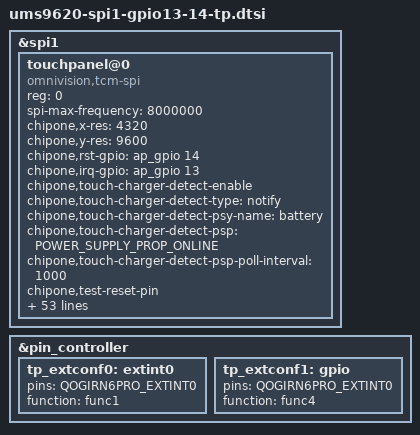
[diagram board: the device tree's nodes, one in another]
// SPDX-License-Identifier: (GPL-2.0+ OR MIT)
/*
 * Unisoc TP dts file
 *
 * Copyright (C) 2020, Unisoc Inc.
 *
 */
&spi1 {
	status = "ok";
	#address-cells = <1>;
	#size-cells = <0>;

	/* Novatek device tree node */
	touchpanel@0 {
		compatible = "omnivision,tcm-spi","tchip,ilitek","novatek,NVT-ts-spi","chipone-tddi";
		reg = <0>; //Same as CS ID
		status = "ok";
		spi-max-frequency = <8000000>;	//4800000,9600000,15000000,19200000

		/*chipone-tddi start*/
		chipone,x-res = <4320>;
		chipone,y-res = <9600>;
		chipone,rst-gpio = <&ap_gpio 14 GPIO_ACTIVE_HIGH>;
		chipone,irq-gpio = <&ap_gpio 13 GPIO_ACTIVE_HIGH>;

		/* Charger detect */
		chipone,touch-charger-detect-enable;
		chipone,touch-charger-detect-type = "notify"; /* notify, poll */
		chipone,touch-charger-detect-psy-name = "battery";
		chipone,touch-charger-detect-psp = "POWER_SUPPLY_PROP_ONLINE";
		chipone,touch-charger-detect-psp-poll-interval = <1000>;

		/* Factory test parameter */
		chipone,test-reset-pin;
		chipone,test-int-pin;
		chipone,test-rawdata;
		chipone,test-rawdata-frames      = <1>;
		chipone,rawdata-min              = <1200>;	//base2000, ±40%
		chipone,rawdata-max              = <2800>;
		chipone,test-noise;
		chipone,test-noise-frames        = <50>;
		chipone,noise-max                = <80>;
		chipone,test-open;
		chipone,open-min                 = <1980>;
		chipone,test-short;
		chipone,short-min                = <500>;
		chipone,test-compensate-cap;
		chipone,compensate-cap-min       = <1>;
		chipone,compensate-cap-max       = <126>;

		/*------------------omnivision_td4375_spi------------------*/
		omnivision,irq-gpio = <&ap_gpio 13 GPIO_ACTIVE_HIGH>; /* IRQF_ONESHOT | IRQF_TRIGGER_LOW */
		omnivision,irq-on-state = <0>;
		omnivision,reset-gpio = <&ap_gpio 14 GPIO_ACTIVE_HIGH>;
		omnivision,reset-on-state = <0>;
		omnivision,reset-active-ms = <20>;
		omnivision,reset-delay-ms = <200>;
		omnivision,power-delay-ms = <200>;
		omnivision,spi-mode = <3>;
		omnivision,byte-delay-us = <0>;
		omnivision,block-delay-us = <0>;
		omnivision,ubl-max-freq = <3000000>;
		omnivision,ubl-byte-delay-us = <20>;

		/*ilitek start*/
		touch,irq-gpio = <&ap_gpio 13 GPIO_ACTIVE_HIGH>;
		touch,eic-irq-gpio = <&eic_async 16 GPIO_ACTIVE_HIGH>;
		touch,reset-gpio = <&ap_gpio 14 GPIO_ACTIVE_HIGH>;
		pinctrl-names = "tp_extconf0","tp_extconf1";
		pinctrl-0 = <&tp_extconf0>;
		pinctrl-1 = <&tp_extconf1>;
		/*ilitek end*/

		/*------------------focaltech_ft8756------------------*/
		focaltech,max-touch-number = <5>;
		focaltech,display-coords =  <0 0 1080 2400>;
		focaltech,reset-gpio = <&ap_gpio 14 GPIO_ACTIVE_HIGH>;
		focaltech,irq-gpio = <&ap_gpio 13 GPIO_ACTIVE_HIGH>;

		/*------------------synaptics_td4320_spi------------------*/
		synaptics,irq-gpio = <&ap_gpio 13 GPIO_ACTIVE_HIGH>;
		synaptics,irq-on-state = <0>;
		synaptics,reset-gpio = <&ap_gpio 14 GPIO_ACTIVE_HIGH>;
		synaptics,reset-on-state = <0>;
		synaptics,reset-active-ms = <20>;
		synaptics,reset-delay-ms = <200>;
		synaptics,power-delay-ms = <200>;
		synaptics,spi-mode = <3>;
		synaptics,byte-delay-us = <0>;
		synaptics,block-delay-us = <0>;
		synaptics,ubl-max-freq = <6000000>;
		synaptics,ubl-byte-delay-us = <20>;

		/*------------------novatek------------------*/
		//novatek,pen-support;
		//novatek,wgp-stylus;

		novatek,reset-gpio = <&ap_gpio 14 GPIO_ACTIVE_HIGH>;
		novatek,irq-gpio = <&ap_gpio 13 GPIO_ACTIVE_HIGH>;
		/* 525 */
		//novatek,swrst-n8-addr = <0x01F01A>;

		/* 672A, 525B, 675, 526, 672C, 523 */
		novatek,swrst-n8-addr = <0x03F0FE>;
		novatek,spi-rd-fast-addr = <0x03F310>;

		/* MP */
		novatek,mp-support-dt;

		#include "nvt-touchscreen-novatek-nt36xxx-spi.dtsi"
	};
};

&pin_controller {

	tp_extconf0: extint0 {
		pins = "QOGIRN6PRO_EXTINT0";
		function = "func1";
	};

	tp_extconf1: gpio {
		pins = "QOGIRN6PRO_EXTINT0";
		function = "func4";
	};
};
